AUTOSAR XML (schema 00046)
standard types defined: float
package /ECU
  ecu instance DJ: associated-com-i-pdu-group=[RX/DJ, TX/DJ]
    can communication controller Observe
  ecu instance Dancer: associated-com-i-pdu-group=[RX/Dancer, TX/Dancer]  # Rhythm is a Dancer!
    can communication controller Observe
  ecu instance Guard
    can communication controller Patrol
package /PDU_GROUPS/RX
  i signal i pdu group Dancer: communication-direction=IN, i-signal-i-pdus=[message1, message4]
  i signal i pdu group DJ: communication-direction=IN, i-signal-i-pdus=[message2, message3, multiplexed_message_static, multiplexed_message_0, multiplexed_message_1]
package /PDU_GROUPS/TX
  i signal i pdu group Dancer: communication-direction=OUT, i-signal-i-pdus=[message2, message3, multiplexed_message_static, multiplexed_message_0, multiplexed_message_1]
  i signal i pdu group DJ: communication-direction=OUT, i-signal-i-pdus=[message1, message4]
package /NMConfig
  nm config A
    can nm cluster NightClub: communication-cluster=Cluster0
      can nm node DJ: controller=DJ/Observe, rx-nm-pdu=alarm_status
      can nm node Dancer: controller=Dancer/Observe, rx-nm-pdu=alarm_status
      can nm node Guard: controller=Patrol, tx-nm-pdu=alarm_status
package /Cluster
  can cluster Cluster0: baudrate=500000, protocol-version=can2.0b, can-fd-baudrate=2000000  # The great CAN cluster
    can physical channel Pch0
      frame MultiplexedMessage: id 0x4, frame-length=2, can-addressing-mode=STANDARD, can-frame-rx-behavior=CAN-FD, can-frame-tx-behavior=CAN-FD
        multiplexed i pdu multiplexed_message:
          length=10
          contained-i-pdu-props=header-id-short-header=0x070809
          dynamic-part{segment-position{segment-byte-order=little-endian, segment-length=8, segment-position=0}, dynamic-part-alternatives=[{i-pdu=multiplexed_message_0, initial-dynamic-part=true, selector-field-code=0}, {i-pdu=multiplexed_message_1, initial-dynamic-part=false, selector-field-code=1}]}
          selector-field-length=2
          selector-field-start-position=6
          static-part=multiplexed_message_static
      frame Message1: id 0x5, frame-length=9, can-addressing-mode=STANDARD, can-frame-rx-behavior=CAN-FD  # Comment1 / Kommentar1
        pdu message1: length=9, contained-i-pdu-props=header-id-short-header=0x0a0B0c
          signal message1_SeqCounter: start 0, 16 bit, little-endian
          signal message1_CRC: start 16, 16 bit, little-endian
          signal signal1: start 36, 3 bit, big-endian, system signal Signal1, init-value=0b101, compu {phys=raw*5 for raw 0..4}, unit=m  # Signal comment! / Signalkommentar!
          signal signal5: start 40, 32 bit, little-endian, base-type=float
          signal signal6: start 32, 1 bit, little-endian, system signal Signal6, init-value=constant-reference=BooleanFalse, compu {0=zero (Nothing / Nichts), phys=raw*0.1 for raw 0..1; unit wp}
          mapping SignalGroup: i-signal-group=message1Group
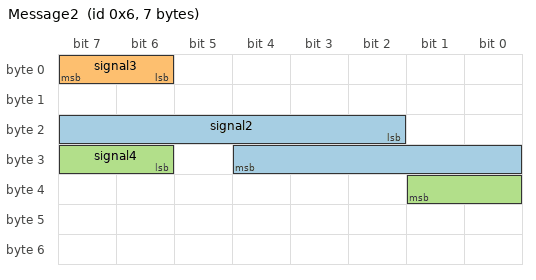
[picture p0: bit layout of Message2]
      frame Message2: id 0x6, frame-length=7, can-addressing-mode=EXTENDED, can-frame-tx-behavior=CAN-FD
        pdu message2: length=7, contained-i-pdu-props=header-id-short-header=0x1D2E3F, transmission-mode-false-timing=cyclic-timing={time-offset=0, time-period=0.1}, transmission-mode-true-timing=cyclic-timing={time-offset=0, time-period=0.2}
          signal signal2: start 18, 11 bit, little-endian, system signal Signal2, base-type=S16
          signal signal3: start 6, 2 bit, little-endian
          signal signal4: start 30, 4 bit, little-endian, system signal Signal4, base-type=U8, compu {1=one (One Comment / Ein Kommentar), 2=two}
      frame Message3: id 0x64, frame-length=6, can-addressing-mode=STANDARD
        secured i pdu message3_secured: length=6, contained-i-pdu-props=header-id-short-header=0x040506, authentication-props=KnockKnock, freshness-props=SmellyCheese, payload=message3_triggering, secure-communication-props=data-id=1337
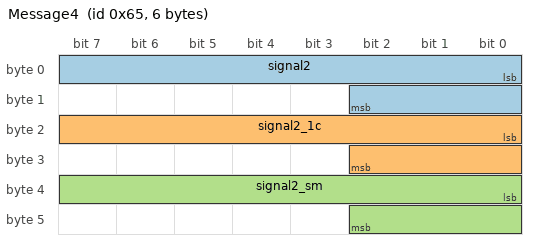
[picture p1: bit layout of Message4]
      frame Message4: id 0x65, frame-length=6, can-addressing-mode=STANDARD
        pdu message4: length=6, unused-bit-pattern=85
          signal signal2: start 0, 11 bit, little-endian, system signal Signal2, base-type=S16
          signal signal2_1c: start 16, 11 bit, little-endian, system signal Signal2_1C, base-type=S16_1C  # Signal comment! (1-Complement)
          signal signal2_sm: start 32, 11 bit, little-endian, system signal Signal2_SM, base-type=S16_SM  # Signal comment! (Sign+Magnitude)
      frame OneToContainThemAll: id 0x66, frame-length=64, can-addressing-mode=STANDARD
        container i pdu OneToContainThemAll: length=64, contained-pdu-triggering=[message1_triggering, message2_triggering, message3_triggering, message3_secured_triggering, multiplexed_triggering], header-type=SHORT-HEADER
      frame AlarmStatus: id 0x3E9, frame-length=1, can-addressing-mode=STANDARD
        nm pdu alarm_status: length=1
          signal FireAlarm: start 0, 1 bit, init-value=constant-reference=BooleanFalse, compu {identical}
      frame MessageWithoutPDU: id 0x3EA, frame-length=8, can-addressing-mode=STANDARD
      pdu triggering message3_triggering: pdu=message3
package /ISignal
  i signal group message1Group: i-signal=[signal1, signal5, signal6], end-to-end-transformation-i-signal-props{transformer=Starscream, data-ids=[123, 124, 125, 126, 127, 128, 129, 130, 131, 132, 133, 134, 135, 136, 137, 138]}
  i signal group message3Group: i-signal=[message3_SeqCounter, message3_CRC], end-to-end-transformation-i-signal-props{transformer=Galvatron, data-ids=321}
package /Transformers
  data transformation set Decepticons
    transformation technology Starscream: protocol=E2E, end-to-end-transformation-description=profile-name=Profile2
    transformation technology Galvatron: protocol=E2E, end-to-end-transformation-description=profile-name=Profile5
package /Constants
  constant specification BooleanTrue: value-spec=literal:true
  constant specification BooleanFalse: value-spec=literal:false
package /ISignalIPdu
  pdu multiplexed_message_static: length=8
    signal MultiplexedStatic: start 0, 3 bit, system signal MultiplexedMessageStatic, init-value=0x7, base-type=S16, compu {identical}
    signal MultiplexedStatic2: start 8, 8 bit, system signal MultiplexedMessageStatic2, init-value=0x7, base-type=S16, compu {identical}
  pdu multiplexed_message_0: length=8
    signal multiplexed_message_selector: start 6, 2 bit, system signal MultiplexedMessageSelector, init-value=0.0, base-type=U8, invalid-value=7, compu {0=SELECT_HELLO, 1=SELECT_WORLD, 3=INVALID_SELECTION}
    signal Hello: start 3, 3 bit, init-value=0, base-type=S16, compu {identical}
  pdu multiplexed_message_1: length=8
    signal World1: start 4, 2 bit, init-value=3, base-type=S16, compu {identical}
    signal World2: start 3, 1 bit, init-value=0, base-type=S16, compu {identical}
    signal multiplexed_message_selector: start 6, 2 bit, system signal MultiplexedMessageSelector, init-value=0.0, base-type=U8, invalid-value=7, compu {0=SELECT_HELLO, 1=SELECT_WORLD, 3=INVALID_SELECTION}
  pdu message3: length=4, contained-i-pdu-props=header-id-short-header=0x010203
    signal message3_CRC: start 0, 8 bit, little-endian
    signal message3_SeqCounter: start 8, 4 bit, little-endian
    mapping SignalGroup: i-signal-group=message3Group
package /SecOCProps
  secure communication props set S
    secure communication authentication props KnockKnock: auth-info-tx-length=10
    secure communication freshness props SmellyCheese: freshness-value-length=32, freshness-value-tx-length=6
package /Unit
  unit meters: display-name=m
  unit wizepoo: display-name=wp
  unit zilch: display-name=NoUnit
package /SystemSignal/SystemSignalInner
  system signal Signal2  # Signal comment!
package /SwBaseType
  4 x base type, all with category=FIXED_LENGTH:
    S16: base-type-size=16, base-type-encoding=2C
    S16_1C: base-type-size=16, base-type-encoding=1C
    S16_SM: base-type-size=16, base-type-encoding=SM
    U8: base-type-size=8, base-type-encoding=NONE
package /System
  system cantools_system: category=SYSTEM_EXTRACT, container-i-pdu-header-byte-order=big-endian
